# C6424_cslr_sys_002 register map
Vendor: Texas Instruments
Peripheral module from a debugger description file.
Registers are 32-bit, access not given, reset 0x0 unless marked. A register's access mark holds for its fields unless they carry their own. Offsets are as the file gives them; lines under a group give offsets from that group; [hi:lo] are bit positions; {n}, {i} and the like mark numbered series; 'fields as' and 'values as' point back to an identical list; <NAME> marks a mode.

## SYS — System Module
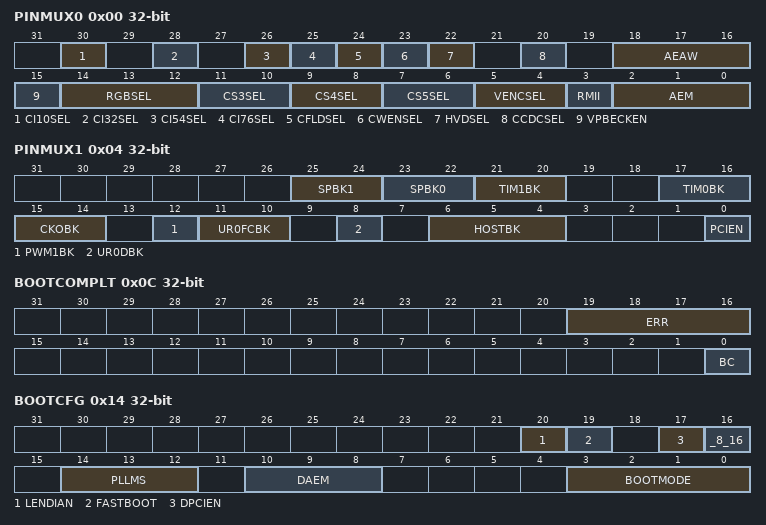
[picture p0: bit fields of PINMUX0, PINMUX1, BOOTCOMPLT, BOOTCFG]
0x00 PINMUX0 — PINMUX Register 0
  [30] CI10SEL rw — CCDC SubBlock CL[1:0] selection: GIO, CCDC data, or McAsp1
  [28] CI32SEL rw — CCDC SubBlock CL[3:2] selection: GIO, CCDC data, or McAsp1
  [26] CI54SEL rw — CCDC SubBlock CL[5:4] selection: GIO, CCDC data, or McAsp1
  [25] CI76SEL rw — CCDC SubBlock CL[7:6] selection: GIO, CCDC data, or McAsp1
  [24] CFLDSEL rw — CCDC SubBlock C_FIELD selection: GIO/EMIF address, or C_FIELD
  [23] CWENSEL rw — CCDC SubBlock C_WEN selection: GIO, or C_WEN
  [22] HVDSEL rw — CCDC SubBlock HD, VD selection: GIO, or HD + VD
  [20] CCDCSEL rw — CCDC SubBlock CCDC Mode: No CCDC, CCDC, or McAsp1
  [18:16] AEAW rw — CCDC SubBlock AEMIF address width selection (Latched at reset)
  [15] VPBECKEN rw — VENC SubBlock VPBECLK enable
  [14:12] RGBSEL rw — VENC SubBlock RGB Mode Select: selects combinations of GIO, LCD_FIELD, RGB666, RGB888
  [11:10] CS3SEL rw — VENC SubBlock EM_CS3 Select: GIO, EM_CS3, VENCLCD_OE
  [9:8] CS4SEL rw — VENC SubBlock EM_CS4 Select: GIO, EM_CS4, or VENC VD
  [7:6] CS5SEL rw — VENC SubBlock EM_CS5 Select: GIO, EM_CS5, or VENC HD
  [5:4] VENCSEL rw — VENC SubBlock VENC Mode: No Venc, 8b or 16b VENC
  [3] RMII rw — VENC SubBlock RMII Select
  [2:0] AEM rw — VENC SubBlock AEMIF pin out type (Latched at reset)
    0=NO_AEMIF; 1=8BIT; 2=16BIT_ASYNC_EMIF
0x04 PINMUX1
  [25:24] SPBK1 rw — McBSP Block McBsp1 Sub-Block Select
  [23:22] SPBK0 rw — McBSP Block McBsp0 Sub-Block Select
  [21:20] TIM1BK rw — Timer1 Block Select
  [17:16] TIM0BK rw — Timer0 Block Select
  [15:14] CKOBK rw — CLKOUT Block select (Note CLKOUT selected by default)
  [12] PWM1BK rw — PWM1 Block select
  [11:10] UR0FCBK rw — UART0 Flow Control Block Select
  [8] UR0DBK rw — UART0 Data Block Select
  [6:4] HOSTBK rw — Host Block Select
  [0] PCIEN ro — Select PCI
0x08 DSPBOOTADDR rw — DSP Boot Address
  [31:0] DSPBOOTADDR — 0x00100000 (Internal Bootloader ROM) or 0x42000000 (EMIFA CS2) Depends on boot mode.
0x0C BOOTCOMPLT — DSP Boot Address
  [19:16] ERR rw — Boot Error 0000: No error 0001 1111: bootloader software detected boot error and aborted boot (Actual error code TBD)
  [0] BC rw — Boot Complete Flag from host This field is only applicable to host boots 0 = Host has not completed booting this device 1 = Host has completed booting this device. DSP Can begin executing from DSPBOOTADDR.
0x14 BOOTCFG — Boot Configuration
  [20] LENDIAN ro — Little Endian Selection (3.5.1.4) 0 = Device is Big Endian 1 = Device is Little Endian This field determines the device endian mode.
  [19] FASTBOOT ro — Fast Boot (3.4.1.1) 0 = No Fast Boot 1 = Fast Boot This field is used by the device bootloader code to determine if it needs to speed up to PLL mode (instead of PLL Bypass mode) before booting.
  [17] DPCIEN ro — PCI Enable Default (3.5.1.5) 0 = PCI disabled 1 = PCI enabled This field affects pin mux control. The default of PINMUX1.PCIEN is set to this DPCIEN value. This field does not affect PCI register setting. User must keep the value on the PCIEN pin constant throughout operation.
  [16] _8_16 ro — EMIFA CS2 Bus Width Default Configuration (3.5.1.1) 0 = EMIFA CS2 space defaults to 8-bit data bus width 1 = EMIFA CS2 space defaults to 16-bit data bus width This field does not affect pin mux control. This field affects EMIFA register setting. The default of EMIFA register field A1CR. ASIZE is set to this 8_16 value.
  [14:12] PLLMS ro — 8-bit EMIFA (Async) Pinout Mode 1 Address Width Default. (3.5.1.3) This field affects pin mux control. The default of pin mux control register PINMUX0.AEAW is set to this DAEAW value. This field does not affect EMIFA register settings. See section 3.5.1.3 for more details.
  [10:8] DAEM ro — EMIFA Pinout Type Default This field affects pin mux control. The default of PINMUX0.AEM is set to this DAEM value. This field does not affect EMIFA register settings.
  [3:0] BOOTMODE ro — This field is used in conjunction with FASTBOOT and DPCIEN to determine the device boot mode.
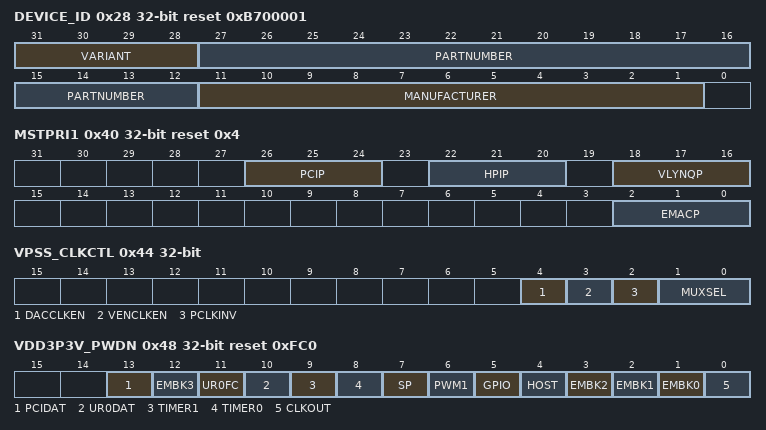
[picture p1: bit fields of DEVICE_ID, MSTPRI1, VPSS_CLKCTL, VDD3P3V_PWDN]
0x28 DEVICE_ID reset 0xB700001
  [31:28] VARIANT ro — Variant (4-Bit) value. DM6437 value: 0000.
  [27:12] PARTNUMBER ro — Part Number (16-Bit) value. DM6437 value: 1011 0111 0010 0001.
  [11:1] MANUFACTURER ro — Manufacturer (11-Bit) value. DM6437 value: 0000 0010 111.
0x30 UHPICTL reset 0x80 — HPI Configuration Register
  [7:0] TIMOUT rw — Sets timeout duration of DMA FIFO flush (in clock cycles)
0x3C MSTPRI0 reset 0x50100 — Master Priorities Reg0
  [10:8] C64X_CFGP rw — DSP CFG bus priority
0x40 MSTPRI1 reset 0x4 — Master Priorities Reg1
  [26:24] PCIP rw — PCI bus priority
  [22:20] HPIP rw — HPI bus priority
  [18:16] VLYNQP rw — VLYNQ bus priority
  [2:0] EMACP rw — EMAC bus priority
0x44 VPSS_CLKCTL — VPSS Clock Control
  [4] DACCLKEN rw — Enable Video DAC clock
    0=DISABLE; 1=ENABLE
  [3] VENCLKEN rw — Enable VPBE/Video Encoder clock
    0=DISABLE; 1=ENABLE
  [2] PCLKINV rw — Invert VPFE pixel clock (PCLK)
    0=DISABLE (VENC clk mux and CCDC receive normal PCLK); 1=ENABLE (VENC clk mux and CCDC receive inverted PCLK)
  [1:0] MUXSEL rw — VPSS clock selection
    0=27MHZ (Use 27MHX (from MXI27) (DAC clock = 27 MHz)); 1=54MHZ (Use 54MHX (from PLLCTRL2) (DAC clock = 54 MHz)); 2=VPBECLK (Use external VPBE Clock input (DAC clock = VPBECLK)); 3=PCLK (Use PCLK from VPFE (DAC clock = off))
0x48 VDD3P3V_PWDN reset 0xFC0 — VDD 3.3v Powerdwn
  [13] PCIDAT rw — PCI Data Block I/O Powerdown Control.
    0=POWERUP (0 = I/O pins powered up (default)); 1=POWERDOWN (1 = I/O pins powered down and not operational. Outputs are tri-stated.)
  [12] EMBK3 rw — EMIFA/VPSS Sub-Block 3 I/O Powerdown Control.
    values as PCIDAT
  [11] UR0FC rw — UART0 Flow Control block I/O Powerdown Control
    0=POWERUP (0 = I/O pins powered up); 1=POWERDOWN (1 = I/O pins powered down and not operational. Outputs are tri-stated. (default))
  [10] UR0DAT rw — UART0 Data Block I/O Powerdown Control
    values as PCIDAT
  [9] TIMER1 rw — Timer1 Block I/O Powerdown Control
    values as PCIDAT
  [8] TIMER0 rw — Timer0 Block I/O Powerdown Control
    values as PCIDAT
  [7] SP rw — Serial Port Block I/O Powerdown Control
    values as PCIDAT
  [6] PWM1 rw — PWM1 Block I/O Powerdown Control
    values as PCIDAT
  [5] GPIO rw — GPIO Block I/O Powerdown Control
    values as PCIDAT
  [4] HOST rw — Host Block I/O Powerdown Control:
    values as PCIDAT
  [3] EMBK2 rw — EMIFA/VPSS Sub-Block 2 I/O Powerdown Control
    values as PCIDAT
  [2] EMBK1 rw — EMIFA/VPSS Sub-Block 1 I/O Powerdown Control
    values as PCIDAT
  [1] EMBK0 rw — EMIFA/VPSS Sub-Block 0 I/O Powerdown Control
    values as PCIDAT
  [0] CLKOUT rw — CLKOUT Block I/O Powerdown Control
    values as PCIDAT
0x4C DDRVTPER — The DDR VTP enable register is used to enable/disable accesses to the DDR VTP register (DDRVTPR).
  [0] EN rw — DDRVTPR access enable.
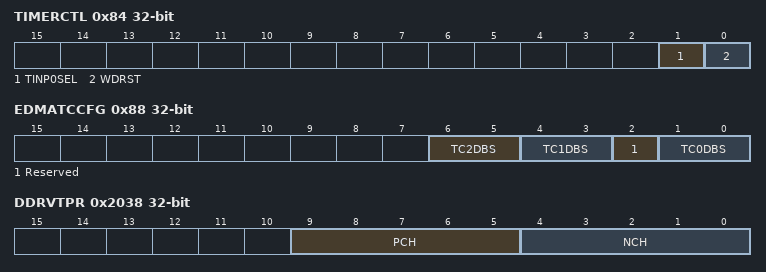
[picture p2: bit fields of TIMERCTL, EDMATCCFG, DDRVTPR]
0x84 TIMERCTL — Timer Control
  [1] TINP0SEL rw — Timer0 External Input (TIN0) Select 0 = Timer0 external input comes directly from the TINP0L pin (default) 1 = Timer0 external input is TINP0L pin divided by 6. For example, if TINP0L = 27MHz, Timer0 input TIN0 is 27MHz / 6 = 4.5 MHz.
  [0] WDRST rw — WatchDog Reset Enable 0 = WatchDog Timer event (WDINT from Timer2) does not cause device reset 1 = WatchDog Timer event (WDINT from Timer2) causes a device max reset (default)
0x88 EDMATCCFG — EDMA TC Configuration Register
  [6:5] TC2DBS rw — EDMA TC2 Default Burst Size 00 = 16 byte 01 = 32 byte 10 = 64 byte (default) 11 = reserved EDMA TC2 is intended for PCI or miscellaneous transfers. TC2 FIFO size is 128 bytes, regardless of Default Burst Size setting.
  [4:3] TC1DBS rw — EDMA TC1 Default Burst Size 00 = 16 byte 01 = 32 byte (default) 10 = 64 byte 11 = reserved EDMA TC1 is intended for high throughput bulk transfers. TC1 FIFO size is 256 bytes, regardless of Default Burst Size setting.
  [2] Reserved — (access N)
  [1:0] TC0DBS rw — EDMA TC0 Default Burst Size 00 = 16 byte (default) 01 = 32 byte 10 = 64 byte 11 = reserved EDMA TC0 is intended for short burst transfers with stringent deadline (e.g. McBSP, McASP). TC0 FIFO size is 128 bytes, regardless of Default Burst Size setting.
0x2038 DDRVTPR — This register is used to moniter the status of VTP IO
  [9:5] PCH rw — P channel value for IO impedance calibration. Following the VTP calibration sequence, this value should be read and written to the PCH field in the VTP IO control register (VTPIOCR).
  [4:0] NCH rw — N channel value for IO impedance calibration. Following the VTP calibration sequence, this value should be read and written to the NCH field in the VTP IO control register (VTPIOCR).
